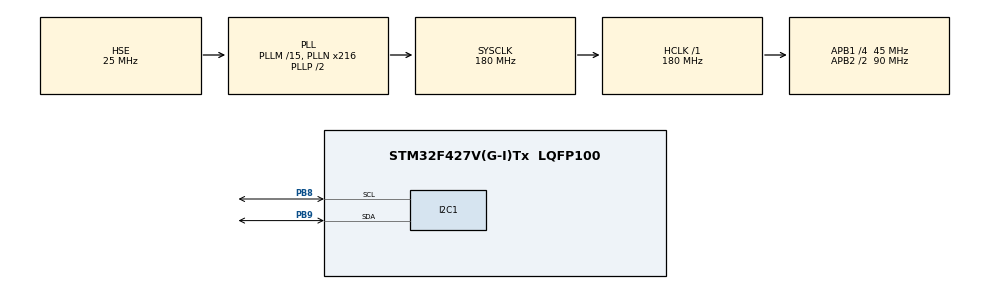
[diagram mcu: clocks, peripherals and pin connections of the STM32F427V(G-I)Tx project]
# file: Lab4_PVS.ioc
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Mcu.Family=STM32F4
RCC.PLLSourceVirtual=RCC_PLLSOURCE_HSE
RCC.CortexFreq_Value=180000000
NVIC.I2C1_EV_IRQn=true\:0\:0\:false\:false\:true\:true\:true
NVIC.TIM6_DAC_IRQn=true\:0\:0\:false\:false\:true\:true\:true
TIM6.Prescaler=8999
VP_TIM6_VS_ClockSourceINT.Mode=Enable_Timer
RCC.APB1CLKDivider=RCC_HCLK_DIV4
RCC.SYSCLKSource=RCC_SYSCLKSOURCE_PLLCLK
ProjectManager.StackSize=0x400
ProjectManager.TargetToolchain=STM32CubeIDE
I2C1.I2C_Mode=I2C_Fast
PH0/OSC_IN.Mode=HSE-External-Oscillator
RCC.HCLKFreq_Value=180000000
PB9.Mode=I2C
RCC.APB2TimFreq_Value=180000000
PH1/OSC_OUT.Signal=RCC_OSC_OUT
RCC.LSE_VALUE=32768
RCC.AHBFreq_Value=180000000
RCC.HSE_VALUE=25000000
board=custom
RCC.VCOOutputFreq_Value=360000000
PH0/OSC_IN.Signal=RCC_OSC_IN
RCC.APB2Freq_Value=90000000
TIM6.Period=9
PH1/OSC_OUT.Mode=HSE-External-Oscillator
Mcu.Name=STM32F427V(G-I)Tx
RCC.48MHZClocksFreq_Value=90000000
RCC.SYSCLKFreq_VALUE=180000000
PB9.Signal=I2C1_SDA
Mcu.Package=LQFP100
ProjectManager.HeapSize=0x200
RCC.HSI_VALUE=16000000
NVIC.PriorityGroup=NVIC_PRIORITYGROUP_4
RCC.APB2CLKDivider=RCC_HCLK_DIV2
RCC.PLLM=15
PB8.Mode=I2C
RCC.PLLN=216
RCC.APB1TimFreq_Value=90000000
PB8.Signal=I2C1_SCL
RCC.APB1Freq_Value=45000000

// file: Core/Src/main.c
/* USER CODE BEGIN Header */
/**
  ******************************************************************************
  * @file           : main.c
  * @brief          : Main program body
  ******************************************************************************
  * @attention
  *
  * <h2><center>&copy; Copyright (c) 2021 STMicroelectronics.
  * All rights reserved.</center></h2>
  *
  * This software component is licensed by ST under BSD 3-Clause license,
  * the "License"; You may not use this file except in compliance with the
  * License. You may obtain a copy of the License at:
  *                        opensource.org/licenses/BSD-3-Clause
  *
  ******************************************************************************
  */
/* USER CODE END Header */

#include "main.h"

/* USER CODE BEGIN Includes */

#include <stdbool.h>

#include "kb.h"
#include "lcd.h"
#include "game.h"

/* USER CODE END Includes */

I2C_HandleTypeDef hi2c1;

TIM_HandleTypeDef htim6;

void SystemClock_Config(void);
static void MX_GPIO_Init(void);
static void MX_I2C1_Init(void);
static void MX_TIM6_Init(void);

int main(void)
{

  /* MCU Configuration--------------------------------------------------------*/

  /* Reset of all peripherals, Initializes the Flash interface and the Systick. */
  HAL_Init();

  /* Configure the system clock */
  SystemClock_Config();

  /* Initialize all configured peripherals */
  MX_GPIO_Init();
  MX_I2C1_Init();
  MX_TIM6_Init();
  /* USER CODE BEGIN 2 */

    kb_init(&hi2c1);
    lcd_init(&hi2c1);
    HAL_TIM_Base_Start_IT(&htim6);

  /* USER CODE END 2 */

  /* Infinite loop */
    while (1) {

    /* USER CODE BEGIN 3 */
        game_step();
    }
  /* USER CODE END 3 */
}

void SystemClock_Config(void)
{
  RCC_OscInitTypeDef RCC_OscInitStruct = {0};
  RCC_ClkInitTypeDef RCC_ClkInitStruct = {0};

  /** Configure the main internal regulator output voltage
  */
  __HAL_RCC_PWR_CLK_ENABLE();
  __HAL_PWR_VOLTAGESCALING_CONFIG(PWR_REGULATOR_VOLTAGE_SCALE1);
  /** Initializes the CPU, AHB and APB busses clocks
  */
  RCC_OscInitStruct.OscillatorType = RCC_OSCILLATORTYPE_HSE;
  RCC_OscInitStruct.HSEState = RCC_HSE_ON;
  RCC_OscInitStruct.PLL.PLLState = RCC_PLL_ON;
  RCC_OscInitStruct.PLL.PLLSource = RCC_PLLSOURCE_HSE;
  RCC_OscInitStruct.PLL.PLLM = 15;
  RCC_OscInitStruct.PLL.PLLN = 216;
  RCC_OscInitStruct.PLL.PLLP = RCC_PLLP_DIV2;
  RCC_OscInitStruct.PLL.PLLQ = 4;
  if (HAL_RCC_OscConfig(&RCC_OscInitStruct) != HAL_OK)
  {
    Error_Handler();
  }
  /** Activate the Over-Drive mode
  */
  if (HAL_PWREx_EnableOverDrive() != HAL_OK)
  {
    Error_Handler();
  }
  /** Initializes the CPU, AHB and APB busses clocks
  */
  RCC_ClkInitStruct.ClockType = RCC_CLOCKTYPE_HCLK|RCC_CLOCKTYPE_SYSCLK
                              |RCC_CLOCKTYPE_PCLK1|RCC_CLOCKTYPE_PCLK2;
  RCC_ClkInitStruct.SYSCLKSource = RCC_SYSCLKSOURCE_PLLCLK;
  RCC_ClkInitStruct.AHBCLKDivider = RCC_SYSCLK_DIV1;
  RCC_ClkInitStruct.APB1CLKDivider = RCC_HCLK_DIV4;
  RCC_ClkInitStruct.APB2CLKDivider = RCC_HCLK_DIV2;

  if (HAL_RCC_ClockConfig(&RCC_ClkInitStruct, FLASH_LATENCY_5) != HAL_OK)
  {
    Error_Handler();
  }
}

static void MX_I2C1_Init(void)
{

  hi2c1.Instance = I2C1;
  hi2c1.Init.ClockSpeed = 400000;
  hi2c1.Init.DutyCycle = I2C_DUTYCYCLE_2;
  hi2c1.Init.OwnAddress1 = 0;
  hi2c1.Init.AddressingMode = I2C_ADDRESSINGMODE_7BIT;
  hi2c1.Init.DualAddressMode = I2C_DUALADDRESS_DISABLE;
  hi2c1.Init.OwnAddress2 = 0;
  hi2c1.Init.GeneralCallMode = I2C_GENERALCALL_DISABLE;
  hi2c1.Init.NoStretchMode = I2C_NOSTRETCH_DISABLE;
  if (HAL_I2C_Init(&hi2c1) != HAL_OK)
  {
    Error_Handler();
  }
  /** Configure Analogue filter
  */
  if (HAL_I2CEx_ConfigAnalogFilter(&hi2c1, I2C_ANALOGFILTER_ENABLE) != HAL_OK)
  {
    Error_Handler();
  }
  /** Configure Digital filter
  */
  if (HAL_I2CEx_ConfigDigitalFilter(&hi2c1, 0) != HAL_OK)
  {
    Error_Handler();
  }

}

static void MX_TIM6_Init(void)
{

  TIM_MasterConfigTypeDef sMasterConfig = {0};

  htim6.Instance = TIM6;
  htim6.Init.Prescaler = 8999;
  htim6.Init.CounterMode = TIM_COUNTERMODE_UP;
  htim6.Init.Period = 9;
  htim6.Init.AutoReloadPreload = TIM_AUTORELOAD_PRELOAD_DISABLE;
  if (HAL_TIM_Base_Init(&htim6) != HAL_OK)
  {
    Error_Handler();
  }
  sMasterConfig.MasterOutputTrigger = TIM_TRGO_RESET;
  sMasterConfig.MasterSlaveMode = TIM_MASTERSLAVEMODE_DISABLE;
  if (HAL_TIMEx_MasterConfigSynchronization(&htim6, &sMasterConfig) != HAL_OK)
  {
    Error_Handler();
  }

}

static void MX_GPIO_Init(void)
{

  /* GPIO Ports Clock Enable */
  __HAL_RCC_GPIOH_CLK_ENABLE();
  __HAL_RCC_GPIOB_CLK_ENABLE();

}

/* USER CODE BEGIN 4 */

void HAL_TIM_PeriodElapsedCallback(TIM_HandleTypeDef * htim) {
    if (htim->Instance == TIM6) {
        static bool lcd = false;

        if (HAL_I2C_GetState(&hi2c1) != HAL_I2C_STATE_READY) {
            return;
        }

        if (lcd) {
            lcd_step(&hi2c1);
        } else {
            kb_scan_step(&hi2c1);
        }

        lcd = !lcd;
    }
}

/* USER CODE END 4 */

void Error_Handler(void)
{
}

/************************ (C) COPYRIGHT STMicroelectronics *****END OF FILE****/
